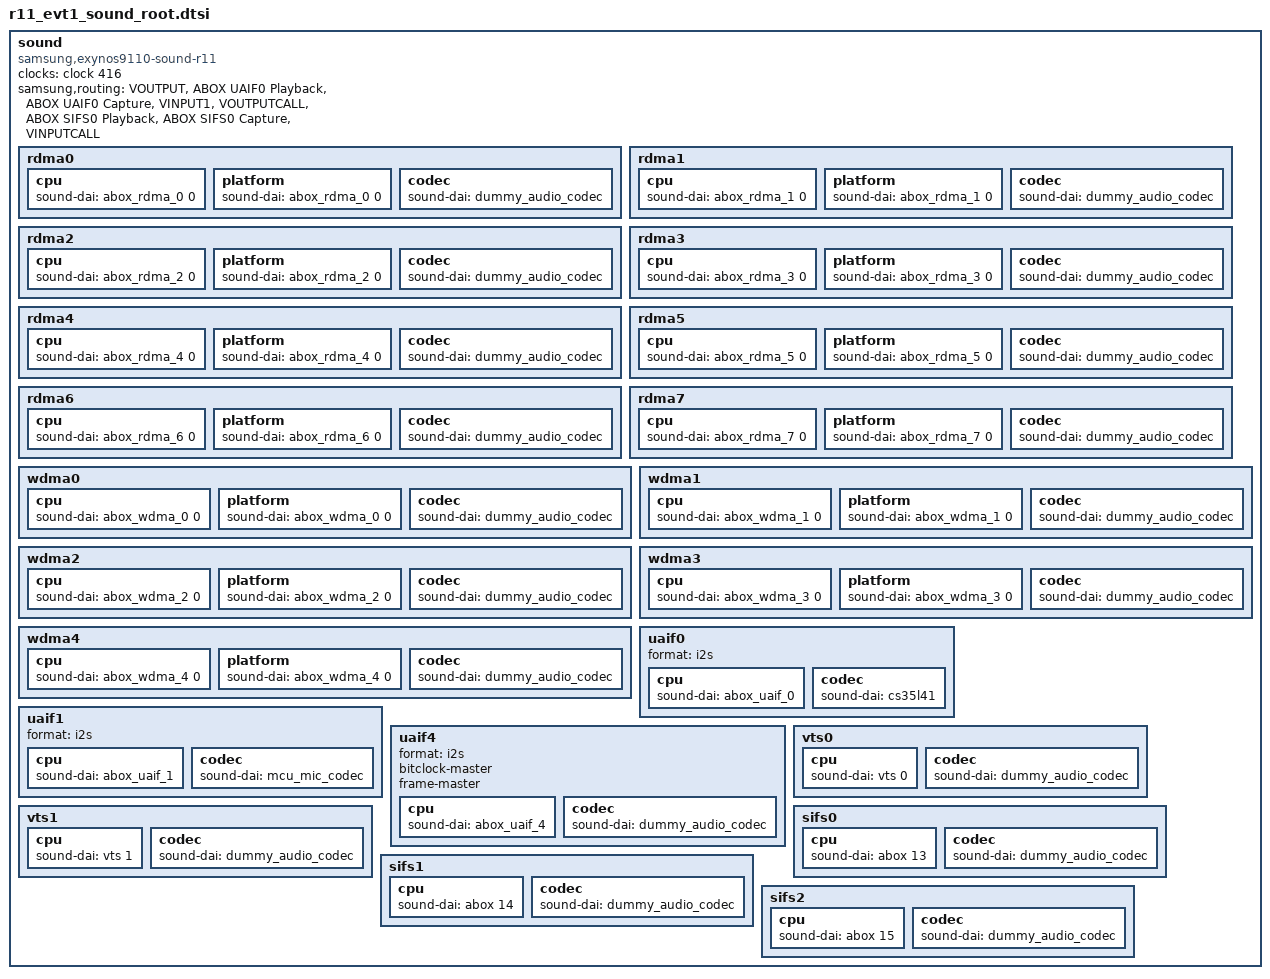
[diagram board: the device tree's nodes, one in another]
/* The whole sound block was copied from the reference platform without
 *  changes. We likely don't need most of it, as most of it are dummy
 *  codecs/dais. Most probably the only useful subnode is uaif@0.
 *  TODO(bsp team): Delete whatever we don't need here.
 */
sound {
	status = "okay";
	compatible = "samsung,exynos9110-sound-r11";

	clock-names = "xclkout";
	/* OSCCLK_AUD =  (CLK_CLKOUT_BASE + 1), where CLK_CLKOUT_BASE = 415*/
	clocks = <&clock 416>;

	samsung,routing = "VOUTPUT", "ABOX UAIF0 Playback",
		"ABOX UAIF0 Capture", "VINPUT1",
		"VOUTPUTCALL", "ABOX SIFS0 Playback",
		"ABOX SIFS0 Capture", "VINPUTCALL";
	/* samsung,aux = <&abox_effect>; */

	rdma0 {
		cpu {
			sound-dai = <&abox_rdma_0 0>;
		};
		platform {
			sound-dai = <&abox_rdma_0 0>;
		};
		codec {
			sound-dai = <&dummy_audio_codec>;
		};
	};
	rdma1 {
		cpu {
			sound-dai = <&abox_rdma_1 0>;
		};
		platform {
			sound-dai = <&abox_rdma_1 0>;
		};
		codec {
			sound-dai = <&dummy_audio_codec>;
		};
	};
	rdma2 {
		cpu {
			sound-dai = <&abox_rdma_2 0>;
		};
		platform {
			sound-dai = <&abox_rdma_2 0>;
		};
		codec {
			sound-dai = <&dummy_audio_codec>;
		};
	};
	rdma3 {
		cpu {
			sound-dai = <&abox_rdma_3 0>;
		};
		platform {
			sound-dai = <&abox_rdma_3 0>;
		};
		codec {
			sound-dai = <&dummy_audio_codec>;
		};
	};
	rdma4 {
		cpu {
			sound-dai = <&abox_rdma_4 0>;
		};
		platform {
			sound-dai = <&abox_rdma_4 0>;
		};
		codec {
			sound-dai = <&dummy_audio_codec>;
		};
	};
	rdma5 {
		cpu {
			sound-dai = <&abox_rdma_5 0>;
		};
		platform {
			sound-dai = <&abox_rdma_5 0>;
		};
		codec {
			sound-dai = <&dummy_audio_codec>;
		};
	};
	rdma6 {
		cpu {
			sound-dai = <&abox_rdma_6 0>;
		};
		platform {
			sound-dai = <&abox_rdma_6 0>;
		};
		codec {
			sound-dai = <&dummy_audio_codec>;
		};
	};
	rdma7 {
		cpu {
			sound-dai = <&abox_rdma_7 0>;
		};
		platform {
			sound-dai = <&abox_rdma_7 0>;
		};
		codec {
			sound-dai = <&dummy_audio_codec>;
		};
	};
	wdma0 {
		cpu {
			sound-dai = <&abox_wdma_0 0>;
		};
		platform {
			sound-dai = <&abox_wdma_0 0>;
		};
		codec {
			sound-dai = <&dummy_audio_codec>;
		};
	};
	wdma1 {
		cpu {
			sound-dai = <&abox_wdma_1 0>;
		};
		platform {
			sound-dai = <&abox_wdma_1 0>;
		};
		codec {
			sound-dai = <&dummy_audio_codec>;
		};
	};
	wdma2 {
		cpu {
			sound-dai = <&abox_wdma_2 0>;
		};
		platform {
			sound-dai = <&abox_wdma_2 0>;
		};
		codec {
			sound-dai = <&dummy_audio_codec>;
		};
	};
	wdma3 {
		cpu {
			sound-dai = <&abox_wdma_3 0>;
		};
		platform {
			sound-dai = <&abox_wdma_3 0>;
		};
		codec {
			sound-dai = <&dummy_audio_codec>;
		};
	};
	wdma4 {
		cpu {
			sound-dai = <&abox_wdma_4 0>;
		};
		platform {
			sound-dai = <&abox_wdma_4 0>;
		};
		codec {
			sound-dai = <&dummy_audio_codec>;
		};
	};
	uaif0 {
		format = "i2s";
		cpu {
			sound-dai = <&abox_uaif_0>;
		};
		codec {
			sound-dai = <&cs35l41>;
		};
	};
	uaif1 {
		format = "i2s";
		cpu {
			sound-dai = <&abox_uaif_1>;
		};
		codec {
			sound-dai = <&mcu_mic_codec>;
		};
	};
	uaif4 {
		format = "i2s";
		bitclock-master;
		frame-master;
		cpu {
			sound-dai = <&abox_uaif_4>;
		};
		codec {
			sound-dai = <&dummy_audio_codec>;
		};
	};
	vts0 {
		cpu {
			sound-dai = <&vts 0>;
		};
		codec {
			sound-dai = <&dummy_audio_codec>;
		};
	};
	vts1 {
		cpu {
			sound-dai = <&vts 1>;
		};
		codec {
			sound-dai = <&dummy_audio_codec>;
		};
	};
	sifs0 {
		cpu {
			sound-dai = <&abox 13>;
		};
		codec {
			sound-dai = <&dummy_audio_codec>;
		};
	};
	sifs1 {
		cpu {
			sound-dai = <&abox 14>;
		};
		codec {
			sound-dai = <&dummy_audio_codec>;
		};
	};
	sifs2 {
		cpu {
			sound-dai = <&abox 15>;
		};
		codec {
			sound-dai = <&dummy_audio_codec>;
		};
	};
};
